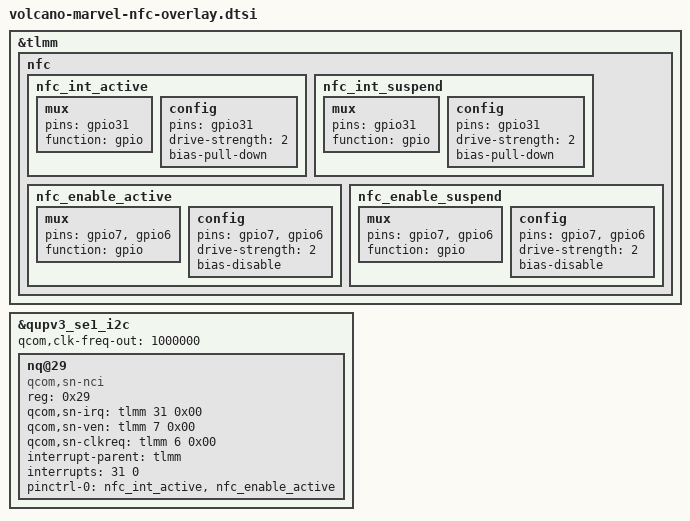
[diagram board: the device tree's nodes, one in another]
&tlmm {
  nfc {
	nfc_int_active: nfc_int_active {
		/* active state */
		mux {
			/* GPIO 31: NFC Read Interrupt */
			pins = "gpio31";
			function = "gpio";
			};
		config {
			pins = "gpio31";
			drive-strength = <2>; /* 2 MA */
			bias-pull-down;
		};
	};
	nfc_int_suspend: nfc_int_suspend {
		/* sleep state */
		mux {
			/* GPIO 31: NFC Read Interrupt */
			pins = "gpio31";
			function = "gpio";
		};
		config {
			pins = "gpio31";
			drive-strength = <2>; /* 2 MA */
			bias-pull-down;
		};
	};
	nfc_enable_active: nfc_enable_active {
		mux {
			/* 7: Enable, 6: CLOCK */
			pins = "gpio7", "gpio6";
			function = "gpio";
		};
		config {
			pins = "gpio7", "gpio6";
			drive-strength = <2>; /* 2 MA */
			bias-disable;
		};
	};
	nfc_enable_suspend: nfc_enable_suspend {
		mux {
			/* 7: Enable, 6: CLOCK */
			pins = "gpio7", "gpio6";
			function = "gpio";
		};
		config {
			pins = "gpio7", "gpio6";
			drive-strength = <2>; /* 2 MA */
			bias-disable;
		};
	};
  };
};

&qupv3_se1_i2c {
	status = "ok";
	qcom,clk-freq-out = <1000000>;
	#address-cells = <1>;
	#size-cells = <0>;
	nq@29 {
		compatible = "qcom,sn-nci";
		reg = <0x29>;
		qcom,sn-irq = <&tlmm 31 0x00>;
		qcom,sn-ven = <&tlmm 7 0x00>;
		qcom,sn-clkreq = <&tlmm 6 0x00>;
		interrupt-parent = <&tlmm>;
		interrupts = <31 0>;
		interrupt-names = "nfc_irq";
		pinctrl-names = "default";
		pinctrl-0 = <&nfc_int_active &nfc_enable_active>;
	};
};
